# M471 register map
File version: 1.0
Registers are 32-bit, read-write, reset 0x0 unless marked. A register's access mark holds for its fields unless they carry their own. Offsets are from the block's base; [hi:lo] are bit positions.

## DFMC — DFMC Register Map
Base 0x4000F000
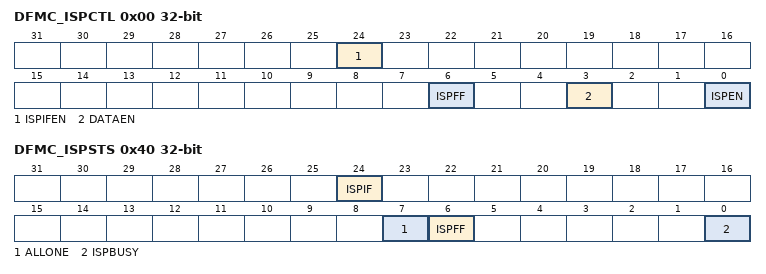
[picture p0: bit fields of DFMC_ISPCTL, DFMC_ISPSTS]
0x00 DFMC_ISPCTL — ISP Control Register
  [24] ISPIFEN — ISP Interrupt Enable bit (Write Protect). Note: This bit is write protected. Refer to the SYS_REGLCTL register.
    0=ISP Interrupt Disabled; 1=ISP Interrupt Enabled
  [6] ISPFF — ISP Fail Flag (Write Protect). This bit is set by hardware when a triggered ISP meets any of the following conditions: This bit needs to be cleared by writing 1 to it. Data Flash writes to itself if DATAEN is set to 0. Erase or Program command at brown-out detected. Destination address is illegal, such as over an available range. Invalid ISP commands. Violate the load code read protection. Checksum or Flash All One Verification is not executed in their valid range. Mass erase is not executed in Data Flash. Note: This bit is write protected. Refer to the SYS_REGLCTL register.
  [3] DATAEN — Data Flash Update Enable Bit (Write Protect). Note: This bit is write protected. Refer to the SYS_REGLCTL register.
    0=Data Flash cannot be updated; 1=Data Flash can be updated
  [0] ISPEN — ISP Enable Bit (Write Protect). ISP function enable bit. Set this bit to enable ISP function. Note: This bit is write protected. Refer to the SYS_REGLCTL register.
    0=ISP function Disabled; 1=ISP function Enabled
0x04 DFMC_ISPADDR — ISP Address Register
  [31:0] ISPADDR — ISP Address. The M471V/M471K is equipped with embedded Data Flash. ISPADDR[1:0] must be kept 00 for ISP 32-bit operation. For CRC32 Checksum Calculation command, this field is the Data Flash starting address for checksum calculation, 256 bytes alignment is necessary for CRC32 checksum calculation. For Data Flash32-bit Program, ISP address needs word alignment (4-byte).
0x08 DFMC_ISPDAT — ISP Data Register
  [31:0] ISPDAT — ISP Data. Write data to this register before ISP program operation. Read data from this register after ISP read operation.
0x0C DFMC_ISPCMD — ISP Command Register
  [6:0] CMD — ISP Command. ISP command table is shown below: The other commands are invalid.
    0=Data FLASH Read; 8=Read Data Flash All-One Result; 11=Read Company ID; 12=Read Device ID; 13=Read Checksum; 33=Data FLASH 32-bit Program; 34=Data FLASH Page Erase. Erase any page in Data Flash; 38=Data FLASH Mass Erase. Erase all pages in Data Flash; 40=Run Data Flash All-One Verification; 45=Run Checksum Calculation
0x10 DFMC_ISPTRG — ISP Trigger Control Register
  [0] ISPGO — ISP Start Trigger (Write Protect). Write 1 to start ISP operation and this bit will be cleared to 0 by hardware automatically when ISP operation is finished. Note: This bit is write protected. Refer to the SYS_REGLCTL register.
    0=ISP operation is finished; 1=ISP is progressed
0x40 DFMC_ISPSTS — ISP Status Register
  [24] ISPIF — ISP Interrupt Flag. Note: Write 1 to clear this bit.
    0=ISP command not finish or ISP fail flag is 0; 1=ISP command finish or ISP fail is 1
  [7] ALLONE — Data Flash All-one Verification Flag. This bit is set by hardware if all of Flash bits are 1, and clear if Flash bits are not all 1 after 'Run Data Flash All-One Verification' complete; this bit also can be clear by writing 1
    0=Data Flash bits are not all 1 after 'Run Data Flash All-One Verification' is complete; 1=All of Data Flash bits are 1 after 'Run Data Flash All-One Verification' is complete
  [6] ISPFF — ISP Fail Flag (Write Protect). This bit is the mirror of ISPFF (DFMC_ISPCTL[6]), it needs to be cleared by writing 1 to DFMC_ISPCTL[6] or DFMC_ISPSTS[6]. This bit is set by hardware when a triggered ISP meets any of the following conditions: Data Flash writes to itself if DATAEN is set to 0. Erase or Program command at brown-out detected. Destination address is illegal, such as over an available range. Invalid ISP commands. Violate the load code read protection. Checksum or Flash All One Verification is not executed in their valid range. Mass erase is not executed in Data Flash. Note: This bit is write protected. Refer to the SYS_REGLCTL register.
  [0] ISPBUSY ro — ISP Busy Flag (Read Only). Write 1 to start ISP operation and this bit will be cleared to 0 by hardware automatically when ISP operation is finished. This bit is the mirror of ISPGO(DFMC_ISPTRG[0]).
    0=ISP operation is finished; 1=ISP is progressed
0x4C DFMC_CYCCTL reset 0x1 — Data Flash Access Cycle Control Register
  [3:0] CYCLE — Data Flash Access Cycle Control (Write Protect). This register is updated by software. The optimized HCLK working frequency range is 192 MHz. Note: This bit is write protected. Refer to the SYS_REGLCTL register.
    0=CPU access with zero wait cycle ; Flash access cycle is 1;; 1=CPU access with one wait cycle if cache miss; Flash access cycle is 1;; 2=CPU access with two wait cycles if cache miss; Flash access cycle is 2;; 3=CPU access with three wait cycles if cache miss; Flash access cycle is 3;; 4=CPU access with four wait cycles if cache miss; Flash access cycle is 4;; 5=CPU access with five wait cycles if cache miss; Flash access cycle is 5;; 6=CPU access with six wait cycles if cache miss; Flash access cycle is 6;; 7=CPU access with seven wait cycles if cache miss; Flash access cycle is 7;; 8=CPU access with eight wait cycles if cache miss; Flash access cycle is 8;
